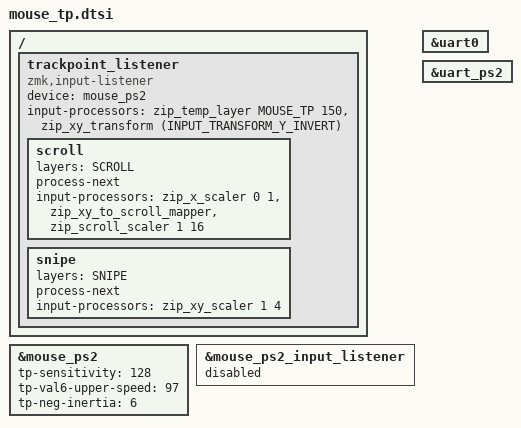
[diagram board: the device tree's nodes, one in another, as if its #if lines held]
#ifdef HAS_MOUSE_TP
  #include <dt-bindings/zmk/mouse.h>
  #include <dt-bindings/zmk/mouse_settings.h>
  #include <behaviors/mouse_keys.dtsi>
  #include <behaviors/mouse_setting.dtsi>

 /*
  * Key Behaviors to adjust settings
  */

  // They key codes below can be used to adjust the TP settings at runtime
  // without needing to recompile the firmware.
  //
  // The values will be logged and saved in the config on the controller flash
  // after 60s (CONFIG_ZMK_SETTINGS_SAVE_DEBOUNCE).
  //
  // On boot the settings will be restored again.
  //
  // If you prefer a more explicit way of configuration, you can also hardcode
  // these settings in `&mouse_ps2`.
  //
  // If you set these settings in `&mouse_ps2`, you will still be able to
  // adjust the values during runtime with these key codes, but after
  // restarting the board the values in `&mouse_ps2` will be restored and not
  // the ones stored in the flash using the key codes.


  // How sensitive the trackpoint is
  #define U_MSS_TP_S_I &mms MS_TP_SENSITIVITY_INCR
  #define U_MSS_TP_S_D &mms MS_TP_SENSITIVITY_DECR


  // The maximum speed the trackpoint will accelerate to
  #define U_MSS_TP_V6_I &mms MS_TP_VALUE6_INCR
  #define U_MSS_TP_V6_D &mms MS_TP_VALUE6_DECR


  // I am not quite sure tbh... default seems fine.
  #define U_MSS_TP_NI_I &mms MS_TP_NEG_INERTIA_INCR
  #define U_MSS_TP_NI_D &mms MS_TP_NEG_INERTIA_DECR


  // How hard you have to press to activate the "Press To Select" feature that
  // lets you tap or press on the trackpoint to click.
  //
  // Not all trackpoints support it and you have to enable
  // `tp-press-to-select;` in `&mouse_ps2` first.
  #define U_MSS_TP_PT_I &mms MS_TP_PTS_THRESHOLD_INCR
  #define U_MSS_TP_PT_D &mms MS_TP_PTS_THRESHOLD_DECR


  // If you mess up the settings, you can use this key code to clear the
  // settings from flash and re-set the default values on the TP.
  //
  // Make sure to wait at least CONFIG_ZMK_SETTINGS_SAVE_DEBOUNCE seconds (60
  // by default) before restarting the board to ensure the settings are
  // written to flash storage.
  #define U_MSS_RESET   &mms MS_RESET


  // If you prefer to set the settings in `&mouse_ps2`, you can use the key
  // codes above to find the settings you like the most and then press this
  // key code to output the settings to the log.
  //
  // Then you can add those values to `&mouse_ps2`
  #define U_MSS_LOG     &mms MS_LOG


  // Only apply these settings on the side that has the TP connected
  // (usually the right side)
  #ifdef MOUSE_PS2_DT_PRESENT

    // Mainline ZMK's input processors (`zip_temp_layer`, `zip_xy_transform`,
    // `zip_xy_to_scroll_mapper`, ...) are not pulled in by `behaviors.dtsi`, so
    // include them here -- only when the TrackPoint is actually built.
    #include <input/processors.dtsi>
    #include <dt-bindings/zmk/input_transform.h>

   /*
    * Input Listener Config
    *
    * This uses mainline ZMK's `zmk,input-listener` instead of the driver
    * module's `zmk,input-listener-ps2` (which is disabled further down).
    *
    * Reason: the module's listener binding only offers
    * `device / xy-swap / x-invert / y-invert / scale-multiplier /
    *  scale-divisor / layer-toggle / layer-toggle-*-ms` -- there is no way to
    * turn stick movement into wheel scrolling. Mainline's listener runs
    * `input-processor`s and supports per-layer overrides, which is exactly what
    * a "hold a key, then move the TrackPoint to scroll" mode needs.
    *
    * Everything the module listener did is reproduced with processors:
    *   layer-toggle             -> `zip_temp_layer`   (layer, timeout-ms)
    *   y-invert                 -> `zip_xy_transform` (INPUT_TRANSFORM_Y_INVERT)
    *   scale-multiplier/divisor -> `zip_xy_scaler`    (mul, div)  [used by snipe: 1/4]
    *
    * On top of the base chain there are two per-layer overrides further down:
    *   `scroll` (`&mo SCROLL`)  converts stick travel into wheel notches
    *   `snipe`  (`&mo SNIPE`)   quarters the pointer speed for fine positioning
    *
    * Difference: the module's `layer-toggle-delay-ms` (how long the stick had to
    * move before the layer activated) has no equivalent -- the layer now turns on
    * with the first movement event. If you would rather avoid the layer popping
    * up right after typing, give the processor's node a
    * `require-prior-idle-ms = <150>;` property.
    */

    / {
      trackpoint_listener: trackpoint_listener {
        compatible = "zmk,input-listener";
        device = <&mouse_ps2>;

        input-processors =
            // Automatically activate the TP layer while the stick moves, and
            // deactivate it 150ms after the last movement.
            <&zip_temp_layer MOUSE_TP 150>,

            // Adjust pointing device axes (was `y-invert;` on the module
            // listener). Add INPUT_TRANSFORM_X_INVERT and/or
            // INPUT_TRANSFORM_XY_SWAP here if you ever need them.
            <&zip_xy_transform (INPUT_TRANSFORM_Y_INVERT)>;

        /*
         * Scroll mode.
         *
         * While the `SCROLL` layer is held (`&mo SCROLL` in the keymap), stick
         * movement is reported as wheel / horizontal wheel instead of pointer
         * movement -- the same idea as the old `&mmm` behaviour.
         */
        scroll {
          layers = <SCROLL>;

          // Also run the base processors above, so the TP layer keeps being
          // toggled while scrolling (its mouse buttons stay usable).
          // Order: the processors below run first, then the base ones.
          process-next;

          input-processors =
              // Horizontal scrolling is OFF. The listener only understands
              // INPUT_REL_X / _Y / _WHEEL / _HWHEEL, and the code-mapper below
              // cannot drop a code -- it only renames the ones it lists. So the
              // sideways axis is zeroed here instead, *before* the mapper:
              // `zip_x_scaler 0 1` multiplies X by 0. That way sideways stick
              // travel produces neither HWHEEL nor a leftover INPUT_REL_X that
              // the base processors (which run afterwards) would feed to the
              // pointer as cursor movement.
              <&zip_x_scaler 0 1>,

              // INPUT_REL_Y -> INPUT_REL_WHEEL, INPUT_REL_X -> INPUT_REL_HWHEEL.
              // (X is already 0 at this point, so the HWHEEL half is inert.)
              <&zip_xy_to_scroll_mapper>,

              // Vertical direction: deliberately NOT inverted any more.
              // Previously a `zip_scroll_transform (INPUT_TRANSFORM_Y_INVERT)`
              // sat here; dropping it swaps "push up" and "push down". Put that
              // line back (between the mapper and the scaler) to swap it again.
              //
              // Stick travel per wheel notch. The fork used a 1-in-8 down-sample
              // of mouse reports; this is the proportional equivalent and keeps
              // the remainder, so slow movement still scrolls.
              // 1/16 = twice as slow as the original 1/8.
              // Raise the second number for slower scrolling, lower it for faster.
              <&zip_scroll_scaler 1 16>;
        };

        /*
         * Precision ("snipe") mode.
         *
         * While the `SNIPE` layer is held (`&mo SNIPE` on the TP layer's top-row
         * `Y` key), stick movement is scaled down to a quarter speed, which makes
         * it much easier to land on small targets.
         *
         * `track-remainders` on `zip_xy_scaler` means the fraction that gets cut
         * off is carried over to the next report, so slow stick movement still
         * accumulates into real cursor travel instead of being thrown away.
         *
         * Declared after `scroll` on purpose: if both layers are held, scroll
         * converts Y to WHEEL first, and the scaler only touches INPUT_REL_X /
         * INPUT_REL_Y -- so snipe slows the pointer without also slowing the
         * scroll. Change `1 4` to `1 2` / `1 8` for a milder / stronger snipe.
         */
        snipe {
          layers = <SNIPE>;
          process-next;
          input-processors = <&zip_xy_scaler 1 4>;
        };
      };
    };


   /*
    * Mouse Driver Settings
    *
    * --------------------------------------------------------------------
    *  Official ("factory") TrackPoint feel -- 官方出厂手感
    * --------------------------------------------------------------------
    *
    * The three values pinned below are the power-on defaults from the IBM
    * "TrackPoint System Version 4.0 Engineering Specification" (YKT3Eext,
    * IBM Corp. 1999), sections 2.4.19.3 / 2.4.19.4 -- i.e. what a genuine
    * ThinkPad TrackPoint is set to when it leaves the factory:
    *
    *   snstvty   E2 81 4A XX   x"80" = 128   input force is divided by 128,
    *                                        so 128 == scale factor 1.00
    *                                        (nominal, no extra gain)
    *   value6    E2 81 60 XX   x"61" =  97   slope of the transfer function
    *                                        segment before the upper plateau.
    *                                        The spec calls 97 "appropriate for
    *                                        a 1024 x 768 pixel display with a
    *                                        2 x acceleration in the mouse
    *                                        driver"
    *   inertia   E2 81 4D XX   x"06" =   6   scaling of the negative-inertia
    *                                        (braking) algorithm
    *
    * Why write them down instead of leaving the TrackPoint alone: the spec
    * states for all three that the value "is not affected by a reset (x"FF")
    * or set default (x"F6") command". They live in the TrackPoint's own NVRAM,
    * so a module whose settings have drifted -- or one a vendor re-flashed with
    * different values -- keeps the off-spec feel forever; the driver's
    * power-on reset cannot bring them back. Writing them from the device tree
    * re-programmes the TrackPoint to the official feel on every boot.
    *
    * Trade-off: with a value present here, the driver refuses to restore that
    * setting from flash (it logs "Not restoring runtime settings ..."), so
    * tweaks made with the TP Set layer (`&mms`) only last until the next boot.
    * Delete the line of whichever setting you want to tune persistently.
    *
    * Note: these are the values for the TrackPoint's OWN transfer function. The
    * pointer-side processors in `trackpoint_listener` above (temp layer, snipe
    * scaler) deliberately add no scaling on the base layer, so nothing in ZMK
    * distorts the official curve.
    */

    &mouse_ps2 {

      // Official default: x"80" (128) -> scale factor 1.00, no gain applied on
      // top of the raw force reading.
      tp-sensitivity = <128>;

      // Official default: x"61" (97). Raise this for a faster top end on a
      // HiDPI screen -- the documented 97 assumes 1024x768 with 2x driver
      // acceleration.
      tp-val6-upper-speed = <97>;

      // Official default: x"06" (6). Larger values brake harder: the cursor
      // stops sooner (and snaps back more) when you let go.
      tp-neg-inertia = <6>;


      // Clicking by pressing harder on the stick.
      // Official state is OFF: the spec's `ptson` bit (E2 47 2C 01) defaults to
      // 0, and the driver only enables the feature when you ask for it here.
      // Not every module implements it (badjeff's T430 does, his newer T460s
      // does not).
      //
      // The official `thr` (Z force required to trigger a press/release,
      // E2 81 5C XX) is x"08" = 8 -- this comment used to claim 10. It only
      // has any effect once press-to-select itself is enabled.
      // tp-press-to-select;
      // tp-press-to-select-threshold = <8>;


      // Adjust axis settings on the TP
      // Works only on some trackpoints, but may be properly considered by the
      // trackpoint's acceleration features (which may or may not have an
      // impact).
      //
      // Alternatively consider achieving the same effect using the
      //  `input-listener` settings below.
      // tp-xy-swap;
      // tp-x-invert;
      // tp-y-invert;


      // Set sampling rate
      //
      // The frequency at which the mouse samples and sends data (in hz).
      // 100 is also the official reset default ("a rate of 100 reports per
      // second is the reset default" in the spec), and the driver only sends
      // the command when this differs from 100 -- so leaving it commented is
      // the official setting. You can try lowering it if you experience
      // connection errors.
      //
      // Higher values than 100 are no improvement in my experience, but will
      // increase battery life and potentially errors in transmissions.
      //
      // These values are allowed: 10,20,40,60,80,100,200
      // sampling-rate = <60>;


      // Disables clicking.
      // Useful when using the PS2 GPIO driver that is prone to
      // erros in transmissions to reduce accidental clicks.
      // disable-clicking;


      // Enable scroll wheel
      // For mouse devices supporting the Intellimouse extension. Not relevant
      // for trackpoints
      // scroll-mode;

    };

    // Enable PS/2 Mouse Devices
    // In `your_keyboard_right.overlay` all devices have `status = "disabled"`.
    // So,they are never compiled into the firmware.
    //
    // Here we enable them, but we do it within the #ifdef HAS_MOUSE_TP code
    // block, which prevents compilation and potential build errors when we
    // undefine HAS_MOUSE_TP in corne_tp.keymap
    &mouse_ps2  {
      status = "okay";
    };

    // Disabled on purpose: mainline ZMK's `zmk,input-listener`
    // (`trackpoint_listener` above) consumes the TrackPoint instead, so that
    // scroll-on-layer is possible. Enabling this too would make every movement
    // report twice.
    &mouse_ps2_input_listener {
      status = "disabled";
    };

    #ifdef MOUSE_PS2_DRIVER_UART

      &uart0 {
        status = "okay";
      };

      &uart_ps2 {
        status="okay";
      };

    #else

      &gpio_ps2  {
        status = "okay";
      };

    #endif  // MOUSE_PS2_DRIVER_UART
  #endif  // MOUSE_PS2_DT_PRESENT
#endif  // HAS_MOUSE_TP
